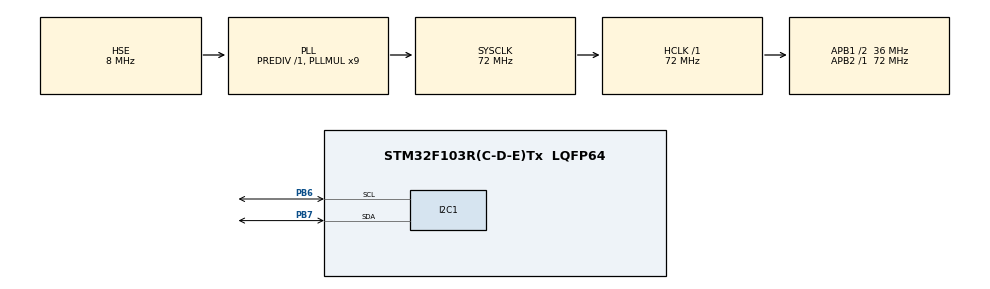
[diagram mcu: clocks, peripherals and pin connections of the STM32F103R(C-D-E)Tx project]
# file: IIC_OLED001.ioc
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Mcu.Family=STM32F1
Mcu.Name=STM32F103R(C-D-E)Tx
Mcu.Package=LQFP64
NVIC.PriorityGroup=NVIC_PRIORITYGROUP_4
PA13.Mode=Serial_Wire
PA13.Signal=SYS_JTMS-SWDIO
PA14.Mode=Serial_Wire
PA14.Signal=SYS_JTCK-SWCLK
PB6.Mode=I2C
PB6.Signal=I2C1_SCL
PB7.Mode=I2C
PB7.Signal=I2C1_SDA
PC14-OSC32_IN.Mode=LSE-External-Oscillator
PC14-OSC32_IN.Signal=RCC_OSC32_IN
PC15-OSC32_OUT.Mode=LSE-External-Oscillator
PC15-OSC32_OUT.Signal=RCC_OSC32_OUT
PD0-OSC_IN.Mode=HSE-External-Oscillator
PD0-OSC_IN.Signal=RCC_OSC_IN
PD1-OSC_OUT.Mode=HSE-External-Oscillator
PD1-OSC_OUT.Signal=RCC_OSC_OUT
ProjectManager.HeapSize=0x200
ProjectManager.StackSize=0x400
ProjectManager.TargetToolchain=MDK-ARM V5.32
RCC.AHBFreq_Value=72000000
RCC.APB1CLKDivider=RCC_HCLK_DIV2
RCC.APB1Freq_Value=36000000
RCC.APB1TimFreq_Value=72000000
RCC.APB2Freq_Value=72000000
RCC.APB2TimFreq_Value=72000000
RCC.HCLKFreq_Value=72000000
RCC.PLLMUL=RCC_PLL_MUL9
RCC.PLLSourceVirtual=RCC_PLLSOURCE_HSE
RCC.SYSCLKFreq_VALUE=72000000
RCC.SYSCLKSource=RCC_SYSCLKSOURCE_PLLCLK
RCC.USBFreq_Value=72000000
board=custom

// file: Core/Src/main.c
/* USER CODE BEGIN Header */
/**
  ******************************************************************************
  * @file           : main.c
  * @brief          : Main program body
  ******************************************************************************
  * @attention
  *
  * Copyright (c) 2023 STMicroelectronics.
  * All rights reserved.
  *
  * This software is licensed under terms that can be found in the LICENSE file
  * in the root directory of this software component.
  * If no LICENSE file comes with this software, it is provided AS-IS.
  *
  ******************************************************************************
  */
/* USER CODE END Header */
#include "main.h"
#include "i2c.h"
#include "gpio.h"
#include "codetab.h"

void SystemClock_Config(void);

/* USER CODE BEGIN 0 */

unsigned char word1[] = "League of Legends";
unsigned char word2[] = "Riot Games.";

	void WriteCmd(unsigned char I2C_Command)//写命令
	{
		HAL_I2C_Mem_Write(&hi2c1, 0x78, 0x00,I2C_MEMADD_SIZE_8BIT,&I2C_Command,1,10000);
	}

	void WriteDat(unsigned char fill_Data)
	{
		HAL_I2C_Mem_Write(&hi2c1, 0x78, 0x40,I2C_MEMADD_SIZE_8BIT,&fill_Data,1,10000);
	}
	void OLED_Fill(unsigned char fill_Data)//全屏填充
	{
		unsigned char m,n;
		for(m=0;m<8;m++)
		{
			WriteCmd(0xb0+m);		//page0-page1
			WriteCmd(0x00);		//low column start address
			WriteCmd(0x10);		//high column start address
			for(n=0;n<128;n++)
				{
					WriteDat(fill_Data);
				}
		}
	}

	void OLED_SetPos(unsigned char x, unsigned char y) //设置起始点坐标
{
	WriteCmd(0xb0+y);
	WriteCmd(((x&0xf0)>>4)|0x10);
	WriteCmd((x&0x0f)|0x01);
}
//展现中文
	void OLED_ShowCN(unsigned char x, unsigned char y, unsigned char N)
{
	unsigned char wm=0;
	unsigned int  adder=32*N;
	OLED_SetPos(x , y);
	for(wm = 0;wm < 16;wm++)
	{
		WriteDat(F16x16[adder]);
		adder += 1;
	}
	OLED_SetPos(x,y + 1);
	for(wm = 0;wm < 16;wm++)
	{
		WriteDat(F16x16[adder]);
		adder += 1;
	}
}
//展现字符串
void OLED_ShowStr(unsigned char x, unsigned char y, unsigned char ch[], unsigned char TextSize)
{
	unsigned char c = 0,i = 0,j = 0;
	switch(TextSize)
	{
		case 1:
		{
			while(ch[j] != '\0')
			{
				c = ch[j] - 32;
				if(x > 126)
				{
					x = 0;
					y++;
				}
				OLED_SetPos(x,y);
				for(i=0;i<6;i++)
					WriteDat(F6x8[c][i]);
				x += 6;
				j++;
			}
		}break;
		case 2:
		{
			while(ch[j] != '\0')
			{
				c = ch[j] - 32;
				if(x > 120)
				{
					x = 0;
					y++;
				}
				OLED_SetPos(x,y);
				for(i=0;i<8;i++)
					WriteDat(F8X16[c*16+i]);
				OLED_SetPos(x,y+1);
				for(i=0;i<8;i++)
					WriteDat(F8X16[c*16+i+8]);
				x += 8;
				j++;
			}
		}break;
	}
}
void OLED_CLS(void)//清屏
{
	OLED_Fill(0x00);
}

void OLED_OFF(void)
{
	WriteCmd(0X8D);  //设置电荷泵
	WriteCmd(0X10);  //关闭电荷泵
	WriteCmd(0XAE);  //OLED休眠
}
void OLED_ON(void)
{
	WriteCmd(0X8D);  //设置电荷泵
	WriteCmd(0X14);  //开启电荷泵
	WriteCmd(0XAF);  //OLED唤醒
}
void OLED_DrawBMP(unsigned char x0,unsigned char y0,unsigned char x1,unsigned char y1,unsigned char BMP[])
{
	unsigned int j=0;
	unsigned char x,y;

  if(y1%8==0)
		y = y1/8;
  else
		y = y1/8 + 1;
	for(y=y0;y<y1;y++)
	{
		OLED_SetPos(x0,y);
    for(x=x0;x<x1;x++)
		{
			WriteDat(BMP[j++]);
		}
	}
}
/* USER CODE END 0 */

int main(void)
{

  /* MCU Configuration--------------------------------------------------------*/

  /* Reset of all peripherals, Initializes the Flash interface and the Systick. */
  HAL_Init();

  /* Configure the system clock */
  SystemClock_Config();

  /* Initialize all configured peripherals */
  MX_GPIO_Init();
  MX_I2C1_Init();

  /* Infinite loop */
  while (1)
  {
		OLED_Fill(0xFF);//全屏点亮
		HAL_Delay(2000);
		OLED_Fill(0x00);//全屏灭
		HAL_Delay(2000);
		for(int i=0;i<5;i++)
		{
			OLED_ShowCN(22+i*16,0,i);//测试显示中文
		}
		HAL_Delay(2000);
		OLED_ShowStr(0,3,word1,1);//测试6*8字符
		OLED_ShowStr(0,4,word2,2);				//测试8*16字符
		HAL_Delay(2000);
		OLED_CLS();//清屏
		OLED_OFF();//测试OLED休眠
		HAL_Delay(2000);
		OLED_ON();//测试OLED休眠后唤醒
		OLED_DrawBMP(0,0,128,8,(unsigned char *)BMP1);//测试BMP位图显示
		HAL_Delay(2000);
  }
}

void SystemClock_Config(void)
{
  RCC_OscInitTypeDef RCC_OscInitStruct = {0};
  RCC_ClkInitTypeDef RCC_ClkInitStruct = {0};

  /** Initializes the RCC Oscillators according to the specified parameters
  * in the RCC_OscInitTypeDef structure.
  */
  RCC_OscInitStruct.OscillatorType = RCC_OSCILLATORTYPE_HSE;
  RCC_OscInitStruct.HSEState = RCC_HSE_ON;
  RCC_OscInitStruct.HSEPredivValue = RCC_HSE_PREDIV_DIV1;
  RCC_OscInitStruct.HSIState = RCC_HSI_ON;
  RCC_OscInitStruct.PLL.PLLState = RCC_PLL_ON;
  RCC_OscInitStruct.PLL.PLLSource = RCC_PLLSOURCE_HSE;
  RCC_OscInitStruct.PLL.PLLMUL = RCC_PLL_MUL9;
  if (HAL_RCC_OscConfig(&RCC_OscInitStruct) != HAL_OK)
  {
    Error_Handler();
  }

  /** Initializes the CPU, AHB and APB buses clocks
  */
  RCC_ClkInitStruct.ClockType = RCC_CLOCKTYPE_HCLK|RCC_CLOCKTYPE_SYSCLK
                              |RCC_CLOCKTYPE_PCLK1|RCC_CLOCKTYPE_PCLK2;
  RCC_ClkInitStruct.SYSCLKSource = RCC_SYSCLKSOURCE_PLLCLK;
  RCC_ClkInitStruct.AHBCLKDivider = RCC_SYSCLK_DIV1;
  RCC_ClkInitStruct.APB1CLKDivider = RCC_HCLK_DIV2;
  RCC_ClkInitStruct.APB2CLKDivider = RCC_HCLK_DIV1;

  if (HAL_RCC_ClockConfig(&RCC_ClkInitStruct, FLASH_LATENCY_2) != HAL_OK)
  {
    Error_Handler();
  }
}

void Error_Handler(void)
{
  __disable_irq();
  while (1)
  {
  }
}
